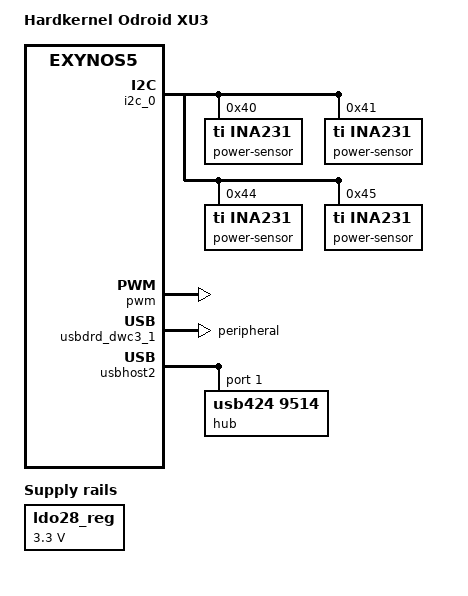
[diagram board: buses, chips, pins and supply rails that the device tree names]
/dts-v1/;
#include "exynos5422-odroidxu3-common.dtsi"
#include "exynos5422-odroidxu3-audio.dtsi"
#include "exynos54xx-odroidxu-leds.dtsi"
/ {
	model = "Hardkernel Odroid XU3";
	compatible = "hardkernel,odroid-xu3", "samsung,exynos5800", "samsung,exynos5";
	aliases {
		ethernet = &ethernet;
	};
};
&i2c_0 {
	status = "okay";
	power-sensor@40 {
		compatible = "ti,ina231";
		reg = <0x40>;
		shunt-resistor = <10000>;
	};
	power-sensor@41 {
		compatible = "ti,ina231";
		reg = <0x41>;
		shunt-resistor = <10000>;
	};
	power-sensor@44 {
		compatible = "ti,ina231";
		reg = <0x44>;
		shunt-resistor = <10000>;
	};
	power-sensor@45 {
		compatible = "ti,ina231";
		reg = <0x45>;
		shunt-resistor = <10000>;
	};
};
&ldo28_reg {
	regulator-name = "dp_p3v3";
	regulator-min-microvolt = <3300000>;
	regulator-max-microvolt = <3300000>;
};
&pwm {
	pinctrl-0 = <&pwm0_out &pwm1_out &pwm2_out &pwm3_out>;
	pinctrl-names = "default";
	status = "okay";
};
&usbdrd_dwc3_1 {
	dr_mode = "peripheral";
};
&usbhost2 {
	#address-cells = <1>;
	#size-cells = <0>;
	hub@1 {
		compatible = "usb424,9514";
		reg = <1>;
		#address-cells = <1>;
		#size-cells = <0>;
		ethernet: ethernet@1 {
			compatible = "usb424,ec00";
			reg = <1>;
			local-mac-address = [00 00 00 00 00 00];  
		};
	};
};
